# PMM__Power_Management_System_7 register map
Vendor: Texas Instruments
Peripheral module from a debugger description file (folder msp430).
Registers are 16-bit, read-write, reset 0x0 unless marked. A register's access mark holds for its fields unless they carry their own. Offsets are as the file gives them; lines under a group give offsets from that group; [hi:lo] are bit positions; {n}, {i} and the like mark numbered series; 'fields as' and 'values as' point back to an identical list; <NAME> marks a mode.

## PMM_Power_Management_System
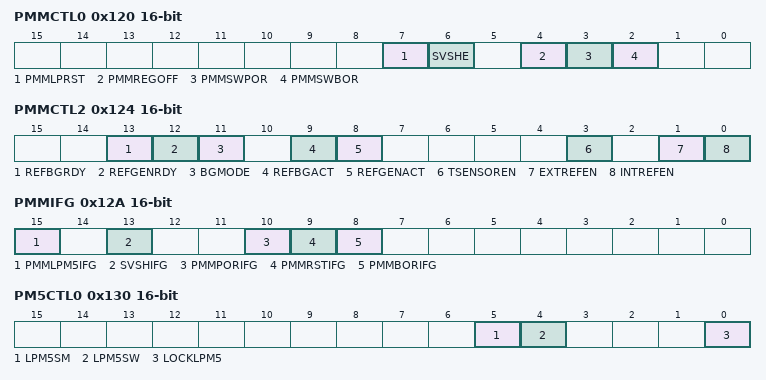
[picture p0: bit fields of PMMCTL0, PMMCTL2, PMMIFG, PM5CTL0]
0x120 PMMCTL0 — PMM Control 0
  [7] PMMLPRST — PMM Low-Power Reset Enable
  [6] SVSHE — SVS high side enable
  [4] PMMREGOFF — PMM Turn Regulator off
  [3] PMMSWPOR — PMM Software POR
  [2] PMMSWBOR — PMM Software BOR
0x122 PMMCTL1 access not given reset not defined — PMM Control 1
0x124 PMMCTL2 — PMM Control 2
  [13] REFBGRDY — REF Reference bandgap ready
  [12] REFGENRDY — REF Reference generator ready
  [11] BGMODE — REF Bandgap mode
  [9] REFBGACT — REF Reference bandgap active
  [8] REFGENACT — REF Reference generator active
  [3] TSENSOREN — Temperature Sensor Enable
  [1] EXTREFEN — External Reference output Enable
  [0] INTREFEN — Internal Reference Enable
0x12A PMMIFG — PMM Interrupt Flag
  [15] PMMLPM5IFG — LPM5 indication Flag
  [13] SVSHIFG — SVS low side interrupt flag
  [10] PMMPORIFG — PMM Software POR interrupt flag
  [9] PMMRSTIFG — PMM RESET pin interrupt flag
  [8] PMMBORIFG — PMM Software BOR interrupt flag
0x12E PMMIE access not given reset not defined — PMM Interrupt Enable
0x130 PM5CTL0 — PMM Power Mode 5 Control Register 0
  [5] LPM5SM — Manual mode for LPM3.5 switch
  [4] LPM5SW — LPMx.5 switch dis/connected
  [0] LOCKLPM5 — Lock I/O pin configuration upon entry/exit to/from LPM5
